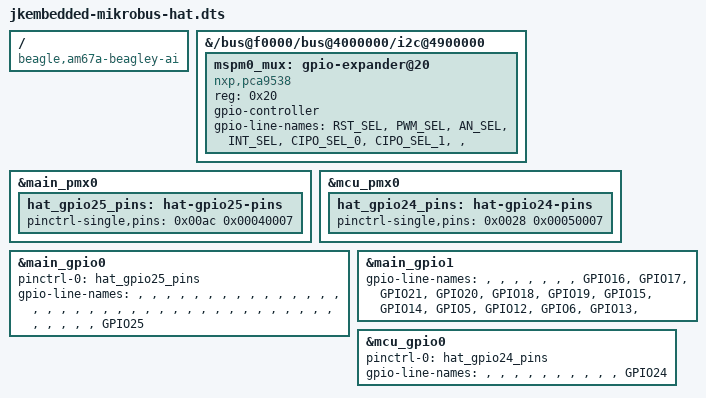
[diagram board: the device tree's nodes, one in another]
/dts-v1/;
/plugin/;

/ {
	compatible = "beagle,am67a-beagley-ai", "ti,am67";

	fragment@0 {
		target-path = "/bus@f0000/bus@4000000/i2c@4900000";
		__overlay__ {
			#address-cells = <1>;
			#size-cells = <0>;

			mspm0_mux: gpio-expander@20 {
				compatible = "nxp,pca9538";
				reg = <0x20>;
				gpio-controller;
				#gpio-cells = <2>;
				gpio-line-names =
					"RST_SEL",
					"PWM_SEL",
					"AN_SEL",
					"INT_SEL",
					"CIPO_SEL_0",
					"CIPO_SEL_1",
					"",
					"";
				status = "okay";
			};
		};
	};

	fragment@1 {
		target = <&main_pmx0>;
		__overlay__ {
			hat_gpio25_pins: hat-gpio25-pins {
				pinctrl-single,pins = <
					0x00ac 0x00040007 /* HAT pin 22 / GPIO25 / P21 / GPIO0_42 input, pull-down */
				>;
			};
		};
	};

	fragment@2 {
		target = <&mcu_pmx0>;
		__overlay__ {
			hat_gpio24_pins: hat-gpio24-pins {
				pinctrl-single,pins = <
					0x0028 0x00050007 /* HAT pin 18 / GPIO24 / C8 / MCU_GPIO0_10 input */
				>;
			};
		};
	};

	fragment@3 {
		target = <&main_gpio0>;
		__overlay__ {
			pinctrl-names = "default";
			pinctrl-0 = <&hat_gpio25_pins>;
			gpio-line-names = "", "", "", "", "", "", "", "", "", "",
				"", "", "", "", "", "", "", "", "", "",
				"", "", "", "", "", "", "", "", "", "",
				"", "", "", "", "", "", "", "", "", "",
				"", "", "GPIO25";
			status = "okay";
		};
	};

	fragment@4 {
		target = <&main_gpio1>;
		__overlay__ {
			gpio-line-names = "", "", "", "", "", "", "", "GPIO16",
				"GPIO17", "GPIO21", "GPIO20", "GPIO18", "GPIO19",
				"GPIO15", "GPIO14", "GPIO5", "GPIO12", "GPIO6",
				"GPIO13", "";
			status = "okay";
		};
	};

	fragment@5 {
		target = <&mcu_gpio0>;
		__overlay__ {
			pinctrl-names = "default";
			pinctrl-0 = <&hat_gpio24_pins>;
			gpio-line-names = "", "", "", "", "", "", "", "", "", "",
				"GPIO24";
			status = "okay";
		};
	};
};
